# nrf54lm20b_application register map
Vendor: Nordic Semiconductor; Series: nrf54l; File version: 1
CPU: CM33 r0p4, little endian, MPU, FPU, 3 interrupt priority bits, 270 interrupts, 4 SAU regions
Registers are 32-bit, read-write, reset 0x0 unless marked. A register's access mark holds for its fields unless they carry their own. Offsets are from the block's base; [hi:lo] are bit positions; lines under a group give offsets from that group; {n}, {i} and the like mark numbered series; 'fields as' and 'values as' point back to an identical list.

## GLOBAL_SPIM00_NS — Serial Peripheral Interface Master with EasyDMA 0
Base 0x4004D000
Same registers: GLOBAL_SPIM20_NS 0x400C6000, GLOBAL_SPIM21_NS 0x400C7000, GLOBAL_SPIM22_NS 0x400C8000, GLOBAL_SPIM23_NS 0x400ED000, GLOBAL_SPIM24_NS 0x400EE000, GLOBAL_SPIM30_NS 0x40104000, GLOBAL_SPIM00_S 0x5004D000, GLOBAL_SPIM20_S 0x500C6000, GLOBAL_SPIM21_S 0x500C7000, GLOBAL_SPIM22_S 0x500C8000, GLOBAL_SPIM23_S 0x500ED000, GLOBAL_SPIM24_S 0x500EE000, GLOBAL_SPIM30_S 0x50104000
0x00 TASKS_START wo — Start SPI transaction
  [0] TASKS_START
    1=Trigger task
0x04 TASKS_STOP wo — Stop SPI transaction
  [0] TASKS_STOP
    1=Trigger task
0x0C TASKS_SUSPEND wo — Suspend SPI transaction
  [0] TASKS_SUSPEND
    1=Trigger task
0x10 TASKS_RESUME wo — Resume SPI transaction
  [0] TASKS_RESUME
    1=Trigger task
0x28 TASKS_DMA group — Peripheral tasks.
  0x08 RX group — Peripheral tasks.
    {0x0+4k} ENABLEMATCH[{k}] (k=0..3) wo — Description collection: Enables the MATCH[n] event by setting the ENABLE[n] bit in the CONFIG register.
      [0] ENABLEMATCH — Enables the MATCH[n] event by setting the ENABLE[n] bit in the CONFIG register.
        1=Trigger task
    {0x10+4k} DISABLEMATCH[{k}] (k=0..3) wo — Description collection: Disables the MATCH[n] event by clearing the ENABLE[n] bit in the CONFIG register.
      [0] DISABLEMATCH — Disables the MATCH[n] event by clearing the ENABLE[n] bit in the CONFIG register.
        1=Trigger task
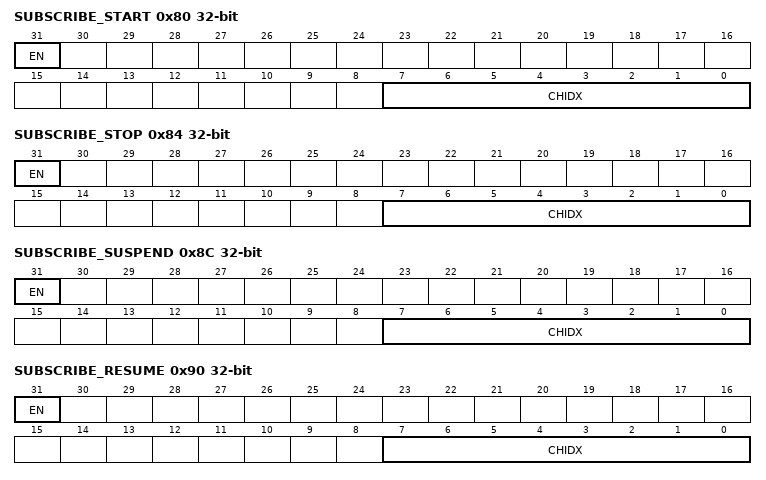
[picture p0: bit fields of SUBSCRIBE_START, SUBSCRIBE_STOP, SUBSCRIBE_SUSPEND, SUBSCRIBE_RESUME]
0x80 SUBSCRIBE_START — Subscribe configuration for task START
  [31] EN
    0=Disabled (Disable subscription); 1=Enabled (Enable subscription)
  [7:0] CHIDX — DPPI channel that task START will subscribe to
0x84 SUBSCRIBE_STOP — Subscribe configuration for task STOP
  [31] EN
    values as SUBSCRIBE_START.EN
  [7:0] CHIDX — DPPI channel that task STOP will subscribe to
0x8C SUBSCRIBE_SUSPEND — Subscribe configuration for task SUSPEND
  [31] EN
    values as SUBSCRIBE_START.EN
  [7:0] CHIDX — DPPI channel that task SUSPEND will subscribe to
0x90 SUBSCRIBE_RESUME — Subscribe configuration for task RESUME
  [31] EN
    values as SUBSCRIBE_START.EN
  [7:0] CHIDX — DPPI channel that task RESUME will subscribe to
0xA8 SUBSCRIBE_DMA group — Subscribe configuration for tasks
  0x08 RX group — Subscribe configuration for tasks
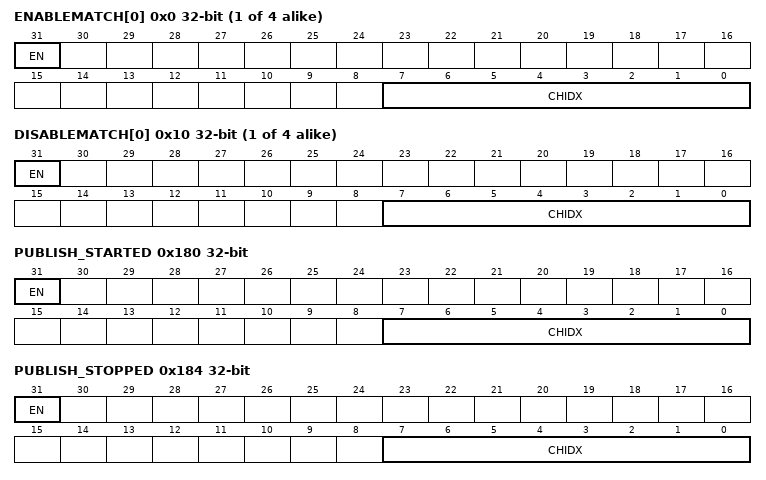
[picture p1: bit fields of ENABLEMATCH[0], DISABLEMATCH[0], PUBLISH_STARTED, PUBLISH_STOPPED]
    {0x0+4k} ENABLEMATCH[{k}] (k=0..3) — Description collection: Subscribe configuration for task ENABLEMATCH[n]
      [31] EN
        values as SUBSCRIBE_START.EN
      [7:0] CHIDX — DPPI channel that task ENABLEMATCH[n] will subscribe to
    {0x10+4k} DISABLEMATCH[{k}] (k=0..3) — Description collection: Subscribe configuration for task DISABLEMATCH[n]
      [31] EN
        values as SUBSCRIBE_START.EN
      [7:0] CHIDX — DPPI channel that task DISABLEMATCH[n] will subscribe to
0x100 EVENTS_STARTED — SPI transaction has started
  [0] EVENTS_STARTED
    0=NotGenerated (Event not generated); 1=Generated (Event generated)
0x104 EVENTS_STOPPED — SPI transaction has stopped
  [0] EVENTS_STOPPED
    values as EVENTS_STARTED.EVENTS_STARTED
0x108 EVENTS_END — End of RXD buffer and TXD buffer reached
  [0] EVENTS_END
    values as EVENTS_STARTED.EVENTS_STARTED
0x14C EVENTS_DMA group — Peripheral events.
  0x00 RX group — Peripheral events.
    0x00 END — Generated after EasyDMA has completed its operation.
      [0] END
        values as EVENTS_STARTED.EVENTS_STARTED
    0x04 READY — Generated when EasyDMA has buffered the .PTR and .MAXCNT registers for the channel, allowing them to be written to prepare for the next sequence.
      [0] READY
        values as EVENTS_STARTED.EVENTS_STARTED
    0x08 BUSERROR — An error occured during the bus transfer.
      [0] BUSERROR
        values as EVENTS_STARTED.EVENTS_STARTED
    {0xC+4k} MATCH[{k}] (k=0..3) — Description collection: Pattern match is detected on the DMA data bus.
      [0] MATCH — Pattern match is detected on the DMA data bus.
        values as EVENTS_STARTED.EVENTS_STARTED
  0x1C TX group — Peripheral events.
    0x00 END — Generated after EasyDMA has completed its operation.
      fields as EVENTS_DMA.RX.END
    0x04 READY — Generated when EasyDMA has buffered the .PTR and .MAXCNT registers for the channel, allowing them to be written to prepare for the next sequence.
      fields as EVENTS_DMA.RX.READY
    0x08 BUSERROR — An error occured during the bus transfer.
      fields as EVENTS_DMA.RX.BUSERROR
0x180 PUBLISH_STARTED — Publish configuration for event STARTED
  [31] EN
    0=Disabled (Disable publishing); 1=Enabled (Enable publishing)
  [7:0] CHIDX — DPPI channel that event STARTED will publish to
0x184 PUBLISH_STOPPED — Publish configuration for event STOPPED
  [31] EN
    values as PUBLISH_STARTED.EN
  [7:0] CHIDX — DPPI channel that event STOPPED will publish to
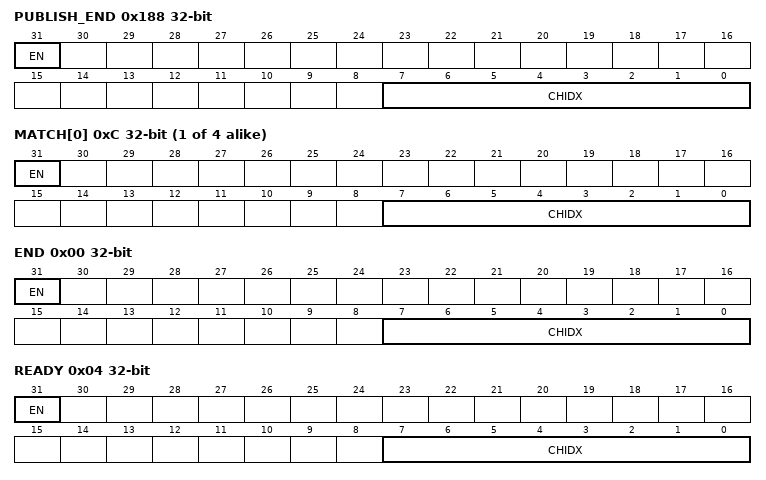
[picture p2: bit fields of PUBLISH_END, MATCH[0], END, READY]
0x188 PUBLISH_END — Publish configuration for event END
  [31] EN
    values as PUBLISH_STARTED.EN
  [7:0] CHIDX — DPPI channel that event END will publish to
0x1CC PUBLISH_DMA group — Publish configuration for events
  0x00 RX group — Publish configuration for events
    0x00 END — Publish configuration for event END
      fields as PUBLISH_END
    0x04 READY — Publish configuration for event READY
      [31] EN
        values as PUBLISH_STARTED.EN
      [7:0] CHIDX — DPPI channel that event READY will publish to
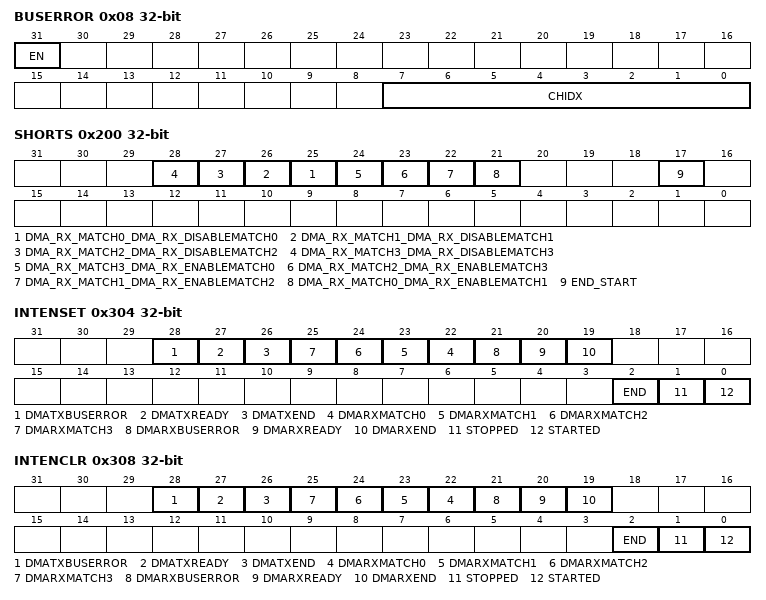
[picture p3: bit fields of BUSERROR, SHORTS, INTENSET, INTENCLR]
    0x08 BUSERROR — Publish configuration for event BUSERROR
      [31] EN
        values as PUBLISH_STARTED.EN
      [7:0] CHIDX — DPPI channel that event BUSERROR will publish to
    {0xC+4k} MATCH[{k}] (k=0..3) — Description collection: Publish configuration for event MATCH[n]
      [31] EN
        values as PUBLISH_STARTED.EN
      [7:0] CHIDX — DPPI channel that event MATCH[n] will publish to
  0x1C TX group — Publish configuration for events
    0x00 END — Publish configuration for event END
      fields as PUBLISH_END
    0x04 READY — Publish configuration for event READY
      fields as PUBLISH_DMA.RX.READY
    0x08 BUSERROR — Publish configuration for event BUSERROR
      fields as PUBLISH_DMA.RX.BUSERROR
0x200 SHORTS — Shortcuts between local events and tasks
  [all] fields
    0=Disabled (Disable shortcut); 1=Enabled (Enable shortcut)
  [n+25] DMA_RX_MATCH{n}_DMA_RX_DISABLEMATCH{n} (n=0..3) — Shortcut between event DMA.RX.MATCH[{n}] and task DMA.RX.DISABLEMATCH[{n}]
  [24] DMA_RX_MATCH3_DMA_RX_ENABLEMATCH0 — Shortcut between event DMA.RX.MATCH[n] and task DMA.RX.ENABLEMATCH[0] Allows daisy-chaining match events.
  [23] DMA_RX_MATCH2_DMA_RX_ENABLEMATCH3 — Shortcut between event DMA.RX.MATCH[n] and task DMA.RX.ENABLEMATCH[3] Allows daisy-chaining match events.
  [22] DMA_RX_MATCH1_DMA_RX_ENABLEMATCH2 — Shortcut between event DMA.RX.MATCH[n] and task DMA.RX.ENABLEMATCH[2] Allows daisy-chaining match events.
  [21] DMA_RX_MATCH0_DMA_RX_ENABLEMATCH1 — Shortcut between event DMA.RX.MATCH[n] and task DMA.RX.ENABLEMATCH[1] Allows daisy-chaining match events.
  [17] END_START — Shortcut between event END and task START
0x304 INTENSET — Enable interrupt
  [all] fields
    on read: 0=Disabled (Read: Disabled); 1=Enabled (Read: Enabled) | on write: 1=Set (Enable)
  [28] DMATXBUSERROR write-1-sets — Write '1' to enable interrupt for event DMATXBUSERROR
  [27] DMATXREADY write-1-sets — Write '1' to enable interrupt for event DMATXREADY
  [26] DMATXEND write-1-sets — Write '1' to enable interrupt for event DMATXEND
  [n+22] DMARXMATCH{n} write-1-sets (n=0..3) — Write '1' to enable interrupt for event DMARXMATCH[{n}]
  [21] DMARXBUSERROR write-1-sets — Write '1' to enable interrupt for event DMARXBUSERROR
  [20] DMARXREADY write-1-sets — Write '1' to enable interrupt for event DMARXREADY
  [19] DMARXEND write-1-sets — Write '1' to enable interrupt for event DMARXEND
  [2] END write-1-sets — Write '1' to enable interrupt for event END
  [1] STOPPED write-1-sets — Write '1' to enable interrupt for event STOPPED
  [0] STARTED write-1-sets — Write '1' to enable interrupt for event STARTED
0x308 INTENCLR — Disable interrupt
  [all] fields
    on read: 0=Disabled (Read: Disabled); 1=Enabled (Read: Enabled) | on write: 1=Clear (Disable)
  [28] DMATXBUSERROR write-1-clears — Write '1' to disable interrupt for event DMATXBUSERROR
  [27] DMATXREADY write-1-clears — Write '1' to disable interrupt for event DMATXREADY
  [26] DMATXEND write-1-clears — Write '1' to disable interrupt for event DMATXEND
  [n+22] DMARXMATCH{n} write-1-clears (n=0..3) — Write '1' to disable interrupt for event DMARXMATCH[{n}]
  [21] DMARXBUSERROR write-1-clears — Write '1' to disable interrupt for event DMARXBUSERROR
  [20] DMARXREADY write-1-clears — Write '1' to disable interrupt for event DMARXREADY
  [19] DMARXEND write-1-clears — Write '1' to disable interrupt for event DMARXEND
  [2] END write-1-clears — Write '1' to disable interrupt for event END
  [1] STOPPED write-1-clears — Write '1' to disable interrupt for event STOPPED
  [0] STARTED write-1-clears — Write '1' to disable interrupt for event STARTED
0x500 ENABLE — Enable SPIM
  [3:0] ENABLE — Enable or disable SPIM
    0=Disabled (Disable SPIM); 7=Enabled (Enable SPIM)
0x52C PRESCALER reset 0x40 — The prescaler is used to set the SPI frequency.
  [6:0] DIVISOR — Core clock to SCK divisor
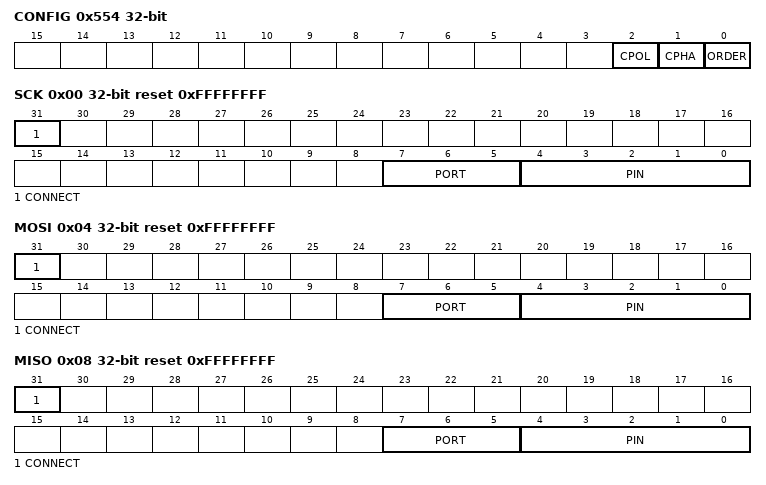
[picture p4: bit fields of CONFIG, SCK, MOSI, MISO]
0x554 CONFIG — Configuration register
  [2] CPOL — Serial clock (SCK) polarity
    0=ActiveHigh; 1=ActiveLow
  [1] CPHA — Serial clock (SCK) phase
    0=Leading (Sample on leading edge of clock, shift serial data on trailing edge); 1=Trailing (Sample on trailing edge of clock, shift serial data on leading edge)
  [0] ORDER — Bit order
    0=MsbFirst (Most significant bit shifted out first); 1=LsbFirst (Least significant bit shifted out first)
0x5AC IFTIMING group — Unspecified
  0x00 RXDELAY reset 0x2 — Sample delay for input serial data on SDI
    [2:0] RXDELAY — Sample delay for input serial data on SDI. The value specifies the number of SPIM core clock cycles delay from the the sampling edge of SCK (leading edge for CONFIG.CPHA = 0, trailing edge for CONFIG.CPHA = 1) until the input serial data is sampled. As en example, if RXDELAY = 0 and CONFIG.CPHA = 0, the input serial data is sampled on the rising edge of SCK.
  0x04 CSNDUR reset 0x2 — Minimum duration between edge of CSN and edge of SCK. When SHORTS.END_START is used, this is also the minimum duration CSN must stay high between transactions.
    [7:0] CSNDUR — Minimum duration between edge of CSN and edge of SCK. When SHORTS.END_START is used, this is the minimum duration CSN must stay high between transactions. The value is specified in number of SPIM core clock cycles.
0x5B4 DCXCNT — DCX configuration
  [3:0] DCXCNT — This register specifies the number of command bytes preceding the data bytes. The PSEL.DCX line will be low during transmission of command bytes and high during transmission of data bytes. Value 0xF indicates that all bytes are command bytes.
0x5B8 CSNPOL — Polarity of CSN output
  [0] CSNPOL_0
    0=LOW (Active low (idle state high)); 1=HIGH (Active high (idle state low))
0x5C0 ORC — Byte transmitted after TXD.MAXCNT bytes have been transmitted in the case when RXD.MAXCNT is greater than TXD.MAXCNT
  [7:0] ORC — Byte transmitted after TXD.MAXCNT bytes have been transmitted in the case when RXD.MAXCNT is greater than TXD.MAXCNT.
0x600 PSEL group — Unspecified
  0x00 SCK reset 0xFFFFFFFF — Pin select for SCK
    [31] CONNECT — Connection
      1=Disconnected; 0=Connected
    [7:5] PORT — Port number
    [4:0] PIN — Pin number
  0x04 MOSI reset 0xFFFFFFFF — Pin select for SDO signal
    fields as PSEL.SCK
  0x08 MISO reset 0xFFFFFFFF — Pin select for SDI signal
    fields as PSEL.SCK
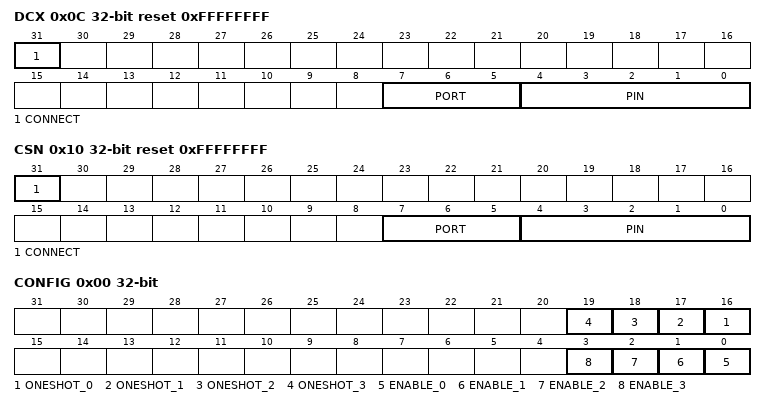
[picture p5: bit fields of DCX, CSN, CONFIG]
  0x0C DCX reset 0xFFFFFFFF — Pin select for DCX signal
    fields as PSEL.SCK
  0x10 CSN reset 0xFFFFFFFF — Pin select for CSN
    fields as PSEL.SCK
0x700 DMA group — Unspecified
  0x00 RX group — Unspecified
    0x04 PTR reset 0x20000000 — RAM buffer start address
      [31:0] PTR — RAM buffer start address for this EasyDMA channel. This address is a word aligned Data RAM address.
    0x08 MAXCNT — Maximum number of bytes in channel buffer
      [15:0] MAXCNT
    0x0C AMOUNT ro — Number of bytes transferred in the last transaction, updated after the END event. For channels that supports the compare match filter, this register is also updated after each MATCH event.
      [15:0] AMOUNT — Number of bytes transferred in the last transaction. In case of NACK error, includes the NACK'ed byte.
    0x14 LIST — EasyDMA list type
      [2:0] TYPE — List type
        0=Disabled (Disable EasyDMA list); 1=ArrayList (Use array list)
    0x1C TERMINATEONBUSERROR — Terminate the transaction if a BUSERROR event is detected.
      [0] ENABLE
        0=Disabled; 1=Enabled
    0x20 BUSERRORADDRESS ro — Address of transaction that generated the last BUSERROR event.
      [31:0] ADDRESS
    0x24 MATCH group — Registers to control the behavior of the pattern matcher engine
      0x00 CONFIG — Configure individual match events
        [n+16] ONESHOT_{n} (n=0..3) — Configure match filter {n} as one-shot or continous
          0=Continuous (Match filter stays enabled until disabled by task); 1=Oneshot (Match filter stays enabled until next data word is received)
        [n] ENABLE_{n} (n=0..3) — Enable match filter {n}
          0=Disabled (Match filter disabled); 1=Enabled (Match filter enabled)
      {0x4+4l} CANDIDATE[{l}] (l=0..3) — Description collection: The data to look for - any match will trigger the MATCH[n] event, if enabled.
        [7:0] DATA — Data to look for
  0x38 TX group — Unspecified
    0x04 PTR reset 0x20000000 — RAM buffer start address
      fields as DMA.RX.PTR
    0x08 MAXCNT — Maximum number of bytes in channel buffer
      [15:0] MAXCNT
    0x0C AMOUNT ro — Number of bytes transferred in the last transaction, updated after the END event. For channels that supports the compare match filter, this register is also updated after each MATCH event.
      fields as DMA.RX.AMOUNT
    0x14 LIST — EasyDMA list type
      fields as DMA.RX.LIST
    0x1C TERMINATEONBUSERROR — Terminate the transaction if a BUSERROR event is detected.
      [0] ENABLE
        0=Disabled; 1=Enabled
    0x20 BUSERRORADDRESS ro — Address of transaction that generated the last BUSERROR event.
      [31:0] ADDRESS

## Notices in the file
Copyright (c) 2010 - 2026, Nordic Semiconductor ASA All rights reserved.
SPDX-License-Identifier: BSD-3-Clause
Redistribution and use in source and binary forms, with or without
modification, are permitted provided that the following conditions are met:
1. Redistributions of source code must retain the above copyright notice, this
list of conditions and the following disclaimer.
2. Redistributions in binary form must reproduce the above copyright
notice, this list of conditions and the following disclaimer in the
documentation and/or other materials provided with the distribution.
3. Neither the name of Nordic Semiconductor ASA nor the names of its
contributors may be used to endorse or promote products derived from this
software without specific prior written permission.
THIS SOFTWARE IS PROVIDED BY THE COPYRIGHT HOLDERS AND CONTRIBUTORS "AS IS"
AND ANY EXPRESS OR IMPLIED WARRANTIES, INCLUDING, BUT NOT LIMITED TO, THE
IMPLIED WARRANTIES OF MERCHANTABILITY, AND FITNESS FOR A PARTICULAR PURPOSE
ARE DISCLAIMED. IN NO EVENT SHALL NORDIC SEMICONDUCTOR ASA OR CONTRIBUTORS BE
LIABLE FOR ANY DIRECT, INDIRECT, INCIDENTAL, SPECIAL, EXEMPLARY, OR
CONSEQUENTIAL DAMAGES (INCLUDING, BUT NOT LIMITED TO, PROCUREMENT OF
SUBSTITUTE GOODS OR SERVICES; LOSS OF USE, DATA, OR PROFITS; OR BUSINESS
INTERRUPTION) HOWEVER CAUSED AND ON ANY THEORY OF LIABILITY, WHETHER IN
CONTRACT, STRICT LIABILITY, OR TORT (INCLUDING NEGLIGENCE OR OTHERWISE)
ARISING IN ANY WAY OUT OF THE USE OF THIS SOFTWARE, EVEN IF ADVISED OF THE
POSSIBILITY OF SUCH DAMAGE.
